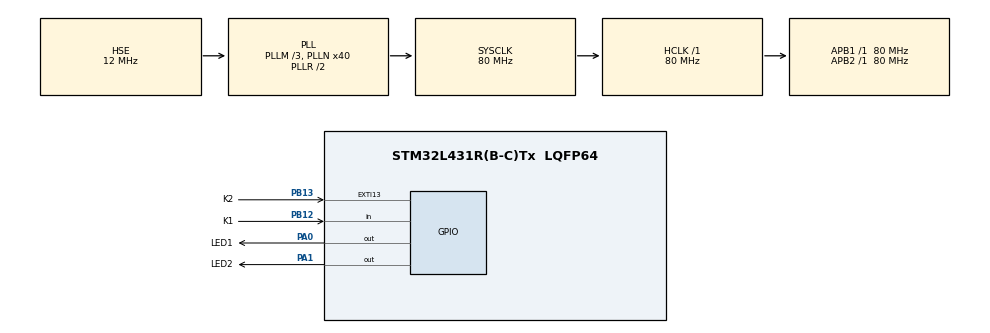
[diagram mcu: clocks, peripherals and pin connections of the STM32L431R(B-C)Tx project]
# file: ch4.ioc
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Mcu.Family=STM32L4
Mcu.Name=STM32L431R(B-C)Tx
Mcu.Package=LQFP64
NVIC.EXTI15_10_IRQn=true\:0\:0\:false\:false\:true\:true\:true\:true
NVIC.PriorityGroup=NVIC_PRIORITYGROUP_4
PA0.GPIO_Label=LED1
PA0.PinState=GPIO_PIN_SET
PA0.Signal=GPIO_Output
PA1.GPIO_Label=LED2
PA1.PinState=GPIO_PIN_SET
PA1.Signal=GPIO_Output
PA13\ (JTMS-SWDIO).Mode=Serial_Wire
PA13\ (JTMS-SWDIO).Signal=SYS_JTMS-SWDIO
PA14\ (JTCK-SWCLK).Mode=Serial_Wire
PA14\ (JTCK-SWCLK).Signal=SYS_JTCK-SWCLK
PB12.GPIO_Label=K1
PB12.GPIO_PuPd=GPIO_PULLDOWN
PB12.Signal=GPIO_Input
PB13.GPIO_Label=K2
PB13.GPIO_ModeDefaultEXTI=GPIO_MODE_IT_RISING
PB13.GPIO_PuPd=GPIO_PULLDOWN
PB13.Signal=GPXTI13
PH0-OSC_IN\ (PH0).Mode=HSE-External-Oscillator
PH0-OSC_IN\ (PH0).Signal=RCC_OSC_IN
PH1-OSC_OUT\ (PH1).Mode=HSE-External-Oscillator
PH1-OSC_OUT\ (PH1).Signal=RCC_OSC_OUT
ProjectManager.HeapSize=0x200
ProjectManager.StackSize=0x400
ProjectManager.TargetToolchain=STM32CubeIDE
RCC.ADCFreq_Value=16000000
RCC.AHBFreq_Value=80000000
RCC.APB1Freq_Value=80000000
RCC.APB1TimFreq_Value=80000000
RCC.APB2Freq_Value=80000000
RCC.APB2TimFreq_Value=80000000
RCC.CortexFreq_Value=80000000
RCC.HCLKFreq_Value=80000000
RCC.HSE_VALUE=12000000
RCC.HSI48_VALUE=48000000
RCC.HSI_VALUE=16000000
RCC.LSE_VALUE=32768
RCC.MSI_VALUE=4000000
RCC.PLLM=3
RCC.PLLN=40
RCC.PLLSourceVirtual=RCC_PLLSOURCE_HSE
RCC.SYSCLKFreq_VALUE=80000000
RCC.SYSCLKSource=RCC_SYSCLKSOURCE_PLLCLK
RCC.VCOOutputFreq_Value=160000000
board=custom

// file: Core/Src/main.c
/* USER CODE BEGIN Header */
/**
  ******************************************************************************
  * @file           : main.c
  * @brief          : Main program body
  ******************************************************************************
  * @attention
  *
  * Copyright (c) 2021 STMicroelectronics.
  * All rights reserved.
  *
  * This software is licensed under terms that can be found in the LICENSE file
  * in the root directory of this software component.
  * If no LICENSE file comes with this software, it is provided AS-IS.
  *
  ******************************************************************************
  */
/* �??1）上电或复位后，系统进行初始化，初始化完成后，LED1先以0.5s的间隔闪�??3次，然后进入正常运行状�?�，LED1�??1s的间隔闪烁�??
 * �??2）按键K1通过轮询的方式控制LED2，每按一次K1，LED2状�?�发生一次改变�??
 * �??3）按键K2通过外部中断的方式控制LED2，每按一次K2，LED2状�?�发生一次改变�??
 * */
/* USER CODE END Header */
#include "main.h"

void SystemClock_Config(void);
static void MX_GPIO_Init(void);

int main(void)
{

  /* MCU Configuration--------------------------------------------------------*/

  /* Reset of all peripherals, Initializes the Flash interface and the Systick. */
  HAL_Init();

  /* Configure the system clock */
  SystemClock_Config();

  /* Initialize all configured peripherals */
  MX_GPIO_Init();
  /* USER CODE BEGIN 2 */
  /* 1. LED1先以0.5s的间隔闪�??3�?? */
  for(int i=0; i<6; i++)
  {
	  HAL_GPIO_TogglePin(LED1_GPIO_Port, LED1_Pin);//电平翻转
	  HAL_Delay(500);
  }
  /* USER CODE END 2 */

  /* Infinite loop */
  /* USER CODE BEGIN WHILE */
  while (1)
  {
	  /* 1. 正常运行LED1间隔1s闪烁 */
	  HAL_GPIO_TogglePin(LED1_GPIO_Port, LED1_Pin);//电平翻转
	  HAL_Delay(1000);

	  /* 2. 每按次K1，LED1状�?�改�? */
	  if(HAL_GPIO_ReadPin(K1_GPIO_Port, K1_Pin) == GPIO_PIN_SET)//判断K1是否按下
	  {
		  while(HAL_GPIO_ReadPin(K1_GPIO_Port, K1_Pin) == GPIO_PIN_SET);//等待K1释放
		  HAL_GPIO_TogglePin(LED2_GPIO_Port, LED2_Pin);//电平翻转
	  }

    /* USER CODE END WHILE */

  }
}

void SystemClock_Config(void)
{
  RCC_OscInitTypeDef RCC_OscInitStruct = {0};
  RCC_ClkInitTypeDef RCC_ClkInitStruct = {0};

  /** Configure the main internal regulator output voltage
  */
  if (HAL_PWREx_ControlVoltageScaling(PWR_REGULATOR_VOLTAGE_SCALE1) != HAL_OK)
  {
    Error_Handler();
  }

  /** Initializes the RCC Oscillators according to the specified parameters
  * in the RCC_OscInitTypeDef structure.
  */
  RCC_OscInitStruct.OscillatorType = RCC_OSCILLATORTYPE_HSE;
  RCC_OscInitStruct.HSEState = RCC_HSE_ON;
  RCC_OscInitStruct.PLL.PLLState = RCC_PLL_ON;
  RCC_OscInitStruct.PLL.PLLSource = RCC_PLLSOURCE_HSE;
  RCC_OscInitStruct.PLL.PLLM = 3;
  RCC_OscInitStruct.PLL.PLLN = 40;
  RCC_OscInitStruct.PLL.PLLP = RCC_PLLP_DIV7;
  RCC_OscInitStruct.PLL.PLLQ = RCC_PLLQ_DIV2;
  RCC_OscInitStruct.PLL.PLLR = RCC_PLLR_DIV2;
  if (HAL_RCC_OscConfig(&RCC_OscInitStruct) != HAL_OK)
  {
    Error_Handler();
  }

  /** Initializes the CPU, AHB and APB buses clocks
  */
  RCC_ClkInitStruct.ClockType = RCC_CLOCKTYPE_HCLK|RCC_CLOCKTYPE_SYSCLK
                              |RCC_CLOCKTYPE_PCLK1|RCC_CLOCKTYPE_PCLK2;
  RCC_ClkInitStruct.SYSCLKSource = RCC_SYSCLKSOURCE_PLLCLK;
  RCC_ClkInitStruct.AHBCLKDivider = RCC_SYSCLK_DIV1;
  RCC_ClkInitStruct.APB1CLKDivider = RCC_HCLK_DIV1;
  RCC_ClkInitStruct.APB2CLKDivider = RCC_HCLK_DIV1;

  if (HAL_RCC_ClockConfig(&RCC_ClkInitStruct, FLASH_LATENCY_4) != HAL_OK)
  {
    Error_Handler();
  }
}

static void MX_GPIO_Init(void)
{
  GPIO_InitTypeDef GPIO_InitStruct = {0};

  /* GPIO Ports Clock Enable */
  __HAL_RCC_GPIOH_CLK_ENABLE();
  __HAL_RCC_GPIOA_CLK_ENABLE();
  __HAL_RCC_GPIOB_CLK_ENABLE();

  /*Configure GPIO pin Output Level */
  HAL_GPIO_WritePin(GPIOA, LED1_Pin|LED2_Pin, GPIO_PIN_SET);

  /*Configure GPIO pins : LED1_Pin LED2_Pin */
  GPIO_InitStruct.Pin = LED1_Pin|LED2_Pin;
  GPIO_InitStruct.Mode = GPIO_MODE_OUTPUT_PP;
  GPIO_InitStruct.Pull = GPIO_NOPULL;
  GPIO_InitStruct.Speed = GPIO_SPEED_FREQ_LOW;
  HAL_GPIO_Init(GPIOA, &GPIO_InitStruct);

  /*Configure GPIO pin : K1_Pin */
  GPIO_InitStruct.Pin = K1_Pin;
  GPIO_InitStruct.Mode = GPIO_MODE_INPUT;
  GPIO_InitStruct.Pull = GPIO_PULLDOWN;
  HAL_GPIO_Init(K1_GPIO_Port, &GPIO_InitStruct);

  /*Configure GPIO pin : K2_Pin */
  GPIO_InitStruct.Pin = K2_Pin;
  GPIO_InitStruct.Mode = GPIO_MODE_IT_RISING;
  GPIO_InitStruct.Pull = GPIO_PULLDOWN;
  HAL_GPIO_Init(K2_GPIO_Port, &GPIO_InitStruct);

  /* EXTI interrupt init*/
  HAL_NVIC_SetPriority(EXTI15_10_IRQn, 0, 0);
  HAL_NVIC_EnableIRQ(EXTI15_10_IRQn);

}

/* USER CODE BEGIN 4 */
/* EXTI回调函数 */
void HAL_GPIO_EXTI_Callback(uint16_t GPIO_Pin)
{
	if(GPIO_Pin == K2_Pin)//判断是否为K2
	{
		HAL_GPIO_TogglePin(LED2_GPIO_Port, LED2_Pin);
	}
}
/* USER CODE END 4 */

void Error_Handler(void)
{
  __disable_irq();
  while (1)
  {
  }
}
